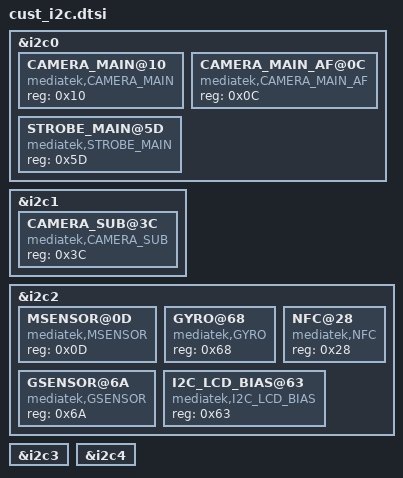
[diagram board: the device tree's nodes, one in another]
/*
 * Generated by MTK SP DrvGen Version 03.13.6 for MT6753. Copyright MediaTek Inc. (C) 2013.
 * Sun Sep 11 02:21:42 2016
 * Do Not Modify the File.
 */

/*************************
 * I2C DTSI File
*************************/

&i2c0 {
	CAMERA_MAIN@10 {
		compatible = "mediatek,CAMERA_MAIN";
		reg = <0x10>;
	};

	CAMERA_MAIN_AF@0C {
		compatible = "mediatek,CAMERA_MAIN_AF";
		reg = <0x0C>;
	};

	STROBE_MAIN@5D {
		compatible = "mediatek,STROBE_MAIN";
		reg = <0x5D>;
	};

};

&i2c1 {
	CAMERA_SUB@3C {
		compatible = "mediatek,CAMERA_SUB";
		reg = <0x3C>;
	};

};

&i2c2 {
	MSENSOR@0D {
		compatible = "mediatek,MSENSOR";
		reg = <0x0D>;
	};

	GYRO@68 {
		compatible = "mediatek,GYRO";
		reg = <0x68>;
	};

	GSENSOR@6A {
		compatible = "mediatek,GSENSOR";
		reg = <0x6A>;
	};

	NFC@28 {
		compatible = "mediatek,NFC";
		reg = <0x28>;
	};

	I2C_LCD_BIAS@63 {
		compatible = "mediatek,I2C_LCD_BIAS";
		reg = <0x63>;
	};

};

&i2c3 {
};

&i2c4 {
};

